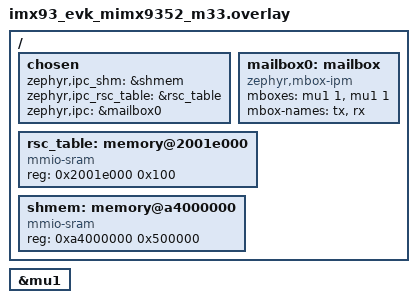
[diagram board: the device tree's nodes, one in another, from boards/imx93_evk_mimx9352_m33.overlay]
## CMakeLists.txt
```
cmake_minimum_required(VERSION 3.28.0)
# Copyright (c) 2020 STMicroelectronics
#
# SPDX-License-Identifier: Apache-2.0
#

find_package(Zephyr REQUIRED HINTS $ENV{ZEPHYR_BASE})

project(openamp_rsc_table_remote)

target_include_directories(app PRIVATE ${LIBMETAL_INCLUDE_DIR} ${OPENAMP_INCLUDE_DIR} ${PLATFORM_DIR})

target_sources(app PRIVATE src/main_remote.c)
```

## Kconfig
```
# Private config options for openamp sample app

# Copyright (c) 2020 STMicroelectronics
# SPDX-License-Identifier: Apache-2.0

# Workaround for not being able to have commas in macro arguments
DT_CHOSEN_Z_IPC := zephyr,ipc

config OPENAMP_IPC_DEV_NAME
	string
	default "$(dt_chosen_label,$(DT_CHOSEN_Z_IPC))"
	help
	  This option specifies the device name for the IPC device to be used

config OPENAMP_IPC_NOTIFY_CHAN
	int "Mailbox channel to use to notify the host"
	default 0

source "Kconfig.zephyr"
```

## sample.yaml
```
sample:
  description: This app provides an example of how to integrate OpenAMP
    with Zephyr including a resource table.
  name: OpenAMP with resource table example integration
tests:
  sample.ipc.openamp_rs_table:
    build_only: true
    platform_allow:
      - stm32mp157c_dk2
      - imx8mp_evk/mimx8ml8/adsp
    integration_platforms:
      - stm32mp157c_dk2
      - imx8mp_evk/mimx8ml8/adsp
    tags:
      - ipm
      - openamp
```

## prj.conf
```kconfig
CONFIG_KERNEL_BIN_NAME="zephyr_openamp_rsc_table"
CONFIG_PRINTK=n
CONFIG_IPM=y
CONFIG_MAIN_STACK_SIZE=1024
CONFIG_HEAP_MEM_POOL_SIZE=1024
CONFIG_OPENAMP=y
CONFIG_OPENAMP_RSC_TABLE_NUM_RPMSG_BUFF=8
CONFIG_OPENAMP_RSC_TABLE=y
CONFIG_OPENAMP_MASTER=n

CONFIG_SHELL=y
CONFIG_SHELL_BACKEND_RPMSG=y
```

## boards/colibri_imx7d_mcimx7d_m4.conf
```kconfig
CONFIG_IPM_IMX_MAX_DATA_SIZE_4=y
CONFIG_OPENAMP_WITH_DCACHE=y
CONFIG_OPENAMP_RSC_TABLE_NUM_RPMSG_BUFF=32

CONFIG_BUILD_OUTPUT_BIN=n
```

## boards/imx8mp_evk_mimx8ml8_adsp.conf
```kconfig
CONFIG_LOG_PRINTK=n
CONFIG_IPM_IMX_MAX_DATA_SIZE_16=n
CONFIG_IPM_IMX_MAX_DATA_SIZE_4=y
CONFIG_OPENAMP_WITH_DCACHE=y
CONFIG_IPM_IMX_FW_READY_REPLY=y
```

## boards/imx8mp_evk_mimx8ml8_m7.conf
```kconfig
CONFIG_LOG_PRINTK=n
CONFIG_IPM_IMX_MAX_DATA_SIZE_16=n
CONFIG_IPM_IMX_MAX_DATA_SIZE_4=y
CONFIG_OPENAMP_WITH_DCACHE=y
CONFIG_LOG=y
CONFIG_LOG_BACKEND_UART=y
CONFIG_LOG_DEFAULT_LEVEL=0
CONFIG_LOG_MODE_MINIMAL=y
CONFIG_OPENAMP_RSC_TABLE_IPM_RX_ID=1
CONFIG_OPENAMP_RSC_TABLE_IPM_TX_ID=0
```

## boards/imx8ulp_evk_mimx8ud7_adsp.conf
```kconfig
CONFIG_LOG_PRINTK=n
CONFIG_OPENAMP_WITH_DCACHE=y

CONFIG_MBOX=y
CONFIG_MBOX_INIT_PRIORITY=3

#vendor-specific resource table
CONFIG_OPENAMP_VENDOR_RSC_TABLE=y
CONFIG_OPENAMP_VENDOR_RSC_TABLE_FILE="nxp_resource_table.c"

#address translation support
CONFIG_OPENAMP_VENDOR_ADDR_TRANSLATION=y
CONFIG_OPENAMP_VENDOR_ADDR_TRANSLATION_FILE="nxp_addr_translation.h"
```

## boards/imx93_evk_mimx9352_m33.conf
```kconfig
CONFIG_CLOCK_CONTROL=y
CONFIG_CONSOLE=y
CONFIG_UART_CONSOLE=y
CONFIG_LOG=y
CONFIG_LOG_MODE_MINIMAL=y
CONFIG_MBOX_INIT_PRIORITY=0
CONFIG_OPENAMP_COPY_RSC_TABLE=y
```

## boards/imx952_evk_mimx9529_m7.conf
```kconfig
CONFIG_LOG=y
CONFIG_SHELL_BACKEND_RPMSG=n
CONFIG_PRINTK=y
CONFIG_OPENAMP_WITH_DCACHE=y
CONFIG_IPM_MBOX=y
CONFIG_MBOX_NXP_IMX_MU=y
CONFIG_LOG_MODE_MINIMAL=y
CONFIG_LOG_DEFAULT_LEVEL=3
CONFIG_OPENAMP_COPY_RSC_TABLE=y
```

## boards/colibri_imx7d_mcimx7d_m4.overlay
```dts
/*
 * Copyright (c) 2024 MAKEEN Energy A/S
 *
 * SPDX-License-Identifier: Apache-2.0
 */

/* Follow the board's documentation to modify the Linux DT accordingly */

/ {
	chosen {
		/* Use OCRAM 128kB because TCM 32kB is too small for the sample */
		zephyr,flash = &ocram_code;
		zephyr,ipc_shm = &ddr_shm;
		zephyr,ipc = &mub;
		zephyr,romstart = &ocram_s_code;
	};

	ddr_shm: memory1@90000000 {
		compatible = "mmio-sram";
		/* use DDR_SYS area as mmio, 0x90000000 0x10000 */
		reg = <0x90000000 0x10000>;
		status = "okay";
	};
};

&mub {
	status = "okay";
};
```

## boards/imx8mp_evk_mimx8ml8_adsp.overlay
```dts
/*
 * Copyright (c) 2023 NXP
 *
 * SPDX-License-Identifier: Apache-2.0
 */

/ {
	chosen {
		/*
		 * shared memory reserved for the inter-processor communication
		 */
		zephyr,ipc_shm = &dspsram3;
		zephyr,ipc = &mailbox0;
	};

	dspsram3: memory@942f0000 {
		compatible = "mmio-sram";
		reg = <0x942f0000 0x110000>;
	};
};

&mailbox0 {
	status = "okay";
};
```

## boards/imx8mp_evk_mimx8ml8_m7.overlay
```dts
/*
 * Copyright 2024 NXP
 *
 * SPDX-License-Identifier: Apache-2.0
 */

/ {
	chosen {
		/*
		 * shared memory reserved for the inter-processor communication
		 */
		zephyr,ipc_shm = &shram;
		zephyr,ipc = &mailbox0;
	};

	shram: memory@55000000 {
		compatible = "mmio-sram";
		reg = <0x55000000 0x500000>;
	};
};

&mailbox0 {
	status = "okay";
};
```

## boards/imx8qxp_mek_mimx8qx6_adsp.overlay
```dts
/*
 * Copyright 2024 NXP
 *
 * SPDX-License-Identifier: Apache-2.0
 */

/ {
	chosen {
		/*
		 * shared memory reserved for the inter-processor communication
		 */
		zephyr,ipc_shm = &dspsram3;
		zephyr,ipc = &mailbox0;
	};

	dspsram3: memory@942f0000 {
		compatible = "mmio-sram";
		reg = <0x942f0000 0x110000>;
	};
};

&mailbox0 {
	status = "okay";
};
```

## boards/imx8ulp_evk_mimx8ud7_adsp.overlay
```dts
/*
 * Copyright 2025 NXP
 *
 * SPDX-License-Identifier: Apache-2.0
 */

/ {
	chosen {
		/*
		 * shared memory reserved for the inter-processor communication
		 */
		zephyr,ipc_shm = &dspsram3;
		zephyr,ipc = &mailbox0;
	};

	mailbox0: mailbox {
		compatible = "zephyr,mbox-ipm";
		mboxes = <&mu3 0>, <&mu3 0>;
		mbox-names = "tx", "rx";
		status = "okay";
	};

	dspsram3: memory@1bef0000 {
		reg = <0x1bef0000 0x110000>;
	};
};

&mu3 {
	status = "okay";
};
```

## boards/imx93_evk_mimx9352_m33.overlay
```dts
/*
 * Copyright 2025 NXP
 *
 * SPDX-License-Identifier: Apache-2.0
 */

/ {
	chosen {
		/*
		 * shared memory reserved for the inter-processor communication
		 */
		zephyr,ipc_shm = &shmem;
		zephyr,ipc_rsc_table = &rsc_table;
		zephyr,ipc = &mailbox0;
	};

	mailbox0: mailbox {
		compatible = "zephyr,mbox-ipm";
		mboxes = <&mu1 1>, <&mu1 1>;
		mbox-names = "tx", "rx";
	};

	rsc_table: memory@2001e000 {
		compatible = "mmio-sram";
		reg = <0x2001e000 0x100>;
	};

	shmem: memory@a4000000 {
		compatible = "mmio-sram";
		reg = <0xa4000000 0x500000>;
	};
};

&mu1 {
	status = "okay";
};
```

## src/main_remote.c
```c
/*
 * Copyright (c) 2020, STMICROELECTRONICS
 *
 * SPDX-License-Identifier: Apache-2.0
 */

#include <zephyr/kernel.h>
#include <zephyr/device.h>
#include <string.h>
#include <stdio.h>
#include <stdlib.h>

#include <zephyr/drivers/ipm.h>

#include <openamp/open_amp.h>
#include <metal/sys.h>
#include <metal/io.h>
#include <resource_table.h>
#include <addr_translation.h>

#ifdef CONFIG_SHELL_BACKEND_RPMSG
#include <zephyr/shell/shell_rpmsg.h>
#endif

#include <zephyr/logging/log.h>
LOG_MODULE_REGISTER(openamp_rsc_table);

#define SHM_DEVICE_NAME	"shm"

/*
 * Lifecycle messages the Linux remoteproc driver exchanges over the mailbox,
 * from its own omap_remoteproc.h. Anything below the first of them is a vring
 * index rather than a command.
 */
#define RP_MBOX_SHUTDOWN     0xFFFFFF14U
#define RP_MBOX_SHUTDOWN_ACK 0xFFFFFF15U

#if !DT_HAS_CHOSEN(zephyr_ipc_shm)
#error "Sample requires definition of shared memory for rpmsg"
#endif

#if CONFIG_IPM_MAX_DATA_SIZE > 0

#define	IPM_SEND(dev, w, id, d, s) ipm_send(dev, w, id, d, s)
#else
#define IPM_SEND(dev, w, id, d, s) ipm_send(dev, w, id, NULL, 0)
#endif

/* Constants derived from device tree */
#define SHM_NODE		DT_CHOSEN(zephyr_ipc_shm)
#define SHM_START_ADDR	DT_REG_ADDR(SHM_NODE)
#define SHM_SIZE		DT_REG_SIZE(SHM_NODE)

#define APP_TASK_STACK_SIZE (1024)

/* Add 1024 extra bytes for the TTY task stack for the "tx_buff" buffer. */
#define APP_TTY_TASK_STACK_SIZE (1536)

K_THREAD_STACK_DEFINE(thread_mng_stack, APP_TASK_STACK_SIZE);
K_THREAD_STACK_DEFINE(thread_rp__client_stack, APP_TASK_STACK_SIZE);
K_THREAD_STACK_DEFINE(thread_tty_stack, APP_TTY_TASK_STACK_SIZE);

static struct k_thread thread_mng_data;
static struct k_thread thread_rp__client_data;
static struct k_thread thread_tty_data;

static const struct device *const ipm_handle =
	DEVICE_DT_GET(DT_CHOSEN(zephyr_ipc));

static metal_phys_addr_t shm_physmap = SHM_START_ADDR;
static metal_phys_addr_t rsc_tab_physmap;

static struct metal_io_region shm_io_data; /* shared memory */
static struct metal_io_region rsc_io_data; /* rsc_table memory */

struct rpmsg_rcv_msg {
	void *data;
	size_t len;
};

static struct metal_io_region *shm_io = &shm_io_data;

static struct metal_io_region *rsc_io = &rsc_io_data;
static struct rpmsg_virtio_device rvdev;

static void *rsc_table;
static struct rpmsg_device *rpdev;

static char rx_sc_msg[20];  /* should receive "Hello world!" */
static struct rpmsg_endpoint sc_ept;
static struct rpmsg_rcv_msg sc_msg = {.data = rx_sc_msg};

static struct rpmsg_endpoint tty_ept;
static struct rpmsg_rcv_msg tty_msg;

static K_SEM_DEFINE(data_sem, 0, 1);
static K_SEM_DEFINE(data_sc_sem, 0, 1);
static K_SEM_DEFINE(data_tty_sem, 0, 1);

/*
 * Answers the shutdown request of the host and parks the core where the host
 * expects to find it.
 *
 * Having asked, the host waits for the acknowledgment and then gives the
 * core two milliseconds to reach WFI before it gives up and reports the stop
 * as timed out. There is nothing left to return to, so park here rather than
 * unwind through a mailbox interrupt the host is about to halt anyway.
 */
static void platform_shutdown(void)
{
	uint32_t ack = RP_MBOX_SHUTDOWN_ACK;

	/*
	 * A full mailbox is the one way this can fail, and dropping the
	 * acknowledgment costs the host a five second wait and leaves it
	 * unable to load anything else, so give the mailbox room to drain.
	 */
	for (int i = 0; i < 100; i++) {
		if (IPM_SEND(ipm_handle, 0, ack, &ack, sizeof(ack)) == 0) {
			break;
		}

		k_busy_wait(100);
	}

	/*
	 * Nothing is left to return to, so park the core here rather than
	 * unwind through a mailbox interrupt the host is about to halt
	 * anyway. k_cpu_idle() is what puts the core in the state the host
	 * looks for before halting it.
	 */
	for (;;) {
		k_cpu_idle();
	}
}

static void platform_ipm_callback(const struct device *dev, void *context,
				  uint32_t id, volatile void *data)
{
	/*
	 * The message itself arrives as the payload; id carries the mailbox
	 * channel it came in on.
	 */
	uint32_t msg = (data != NULL) ? *(volatile uint32_t *)data : 0;

	LOG_DBG("%s: msg 0x%08x received from mb %d", __func__, msg, id);

	if (msg == RP_MBOX_SHUTDOWN) {
		platform_shutdown();
	}

	k_sem_give(&data_sem);
}

static int rpmsg_recv_cs_callback(struct rpmsg_endpoint *ept, void *data,
				  size_t len, uint32_t src, void *priv)
{
	memcpy(sc_msg.data, data, len);
	sc_msg.len = len;
	k_sem_give(&data_sc_sem);

	return RPMSG_SUCCESS;
}

static int rpmsg_recv_tty_callback(struct rpmsg_endpoint *ept, void *data,
				   size_t len, uint32_t src, void *priv)
{
	struct rpmsg_rcv_msg *msg = priv;

	rpmsg_hold_rx_buffer(ept, data);
	msg->data = data;
	msg->len = len;
	k_sem_give(&data_tty_sem);

	return RPMSG_SUCCESS;
}

static void receive_message(unsigned char **msg, unsigned int *len)
{
	int status = k_sem_take(&data_sem, K_FOREVER);

	if (status == 0) {
		rproc_virtio_notified(rvdev.vdev, VRING1_ID);
	}
}

static void new_service_cb(struct rpmsg_device *rdev, const char *name,
			   uint32_t src)
{
	LOG_ERR("%s: unexpected ns service receive for name %s",
		__func__, name);
}

int mailbox_notify(void *priv, uint32_t id)
{
	ARG_UNUSED(priv);

	LOG_DBG("%s: msg received", __func__);
	IPM_SEND(ipm_handle, 0, id, &id, 4);

	return 0;
}

int platform_init(void)
{
	int rsc_size;
	struct metal_init_params metal_params = METAL_INIT_DEFAULTS;
	int status;

	status = metal_init(&metal_params);
	if (status) {
		LOG_ERR("metal_init: failed: %d", status);
		return -1;
	}

	/* declare shared memory region */
	metal_io_init(shm_io, (void *)SHM_START_ADDR, &shm_physmap,
		      SHM_SIZE, -1, 0, addr_translation_get_ops(shm_physmap));

	/* declare resource table region */
	rsc_table_get(&rsc_table, &rsc_size);
	rsc_tab_physmap = (uintptr_t)rsc_table;

	metal_io_init(rsc_io, rsc_table,
		      &rsc_tab_physmap, rsc_size, -1, 0, NULL);

	/* setup IPM */
	if (!device_is_ready(ipm_handle)) {
		LOG_ERR("IPM device is not ready");
		return -1;
	}

	ipm_register_callback(ipm_handle, platform_ipm_callback, NULL);

	status = ipm_set_enabled(ipm_handle, 1);
	if (status) {
		LOG_ERR("ipm_set_enabled failed");
		return -1;
	}

	return 0;
}

static void cleanup_system(void)
{
	ipm_set_enabled(ipm_handle, 0);
	rpmsg_deinit_vdev(&rvdev);
	metal_finish();
}

struct  rpmsg_device *
platform_create_rpmsg_vdev(unsigned int vdev_index,
			   unsigned int role,
			   void (*rst_cb)(struct virtio_device *vdev),
			   rpmsg_ns_bind_cb ns_cb)
{
	struct fw_rsc_vdev_vring *vring_rsc;
	struct virtio_device *vdev;
	int ret;

	vdev = rproc_virtio_create_vdev(VIRTIO_DEV_DEVICE, VDEV_ID,
					rsc_table_to_vdev(rsc_table),
					rsc_io, NULL, mailbox_notify, NULL);

	if (!vdev) {
		LOG_ERR("failed to create vdev");
		return NULL;
	}

	/* wait master rpmsg init completion */
	rproc_virtio_wait_remote_ready(vdev);

	vring_rsc = rsc_table_get_vring0(rsc_table);
	ret = rproc_virtio_init_vring(vdev, 0, vring_rsc->notifyid,
				      (void *)vring_rsc->da, rsc_io,
				      vring_rsc->num, vring_rsc->align);
	if (ret) {
		LOG_ERR("failed to init vring 0");
		goto failed;
	}

	vring_rsc = rsc_table_get_vring1(rsc_table);
	ret = rproc_virtio_init_vring(vdev, 1, vring_rsc->notifyid,
				      (void *)vring_rsc->da, rsc_io,
				      vring_rsc->num, vring_rsc->align);
	if (ret) {
		LOG_ERR("failed to init vring 1");
		goto failed;
	}

	ret = rpmsg_init_vdev(&rvdev, vdev, ns_cb, shm_io, NULL);
	if (ret) {
		LOG_ERR("failed rpmsg_init_vdev");
		goto failed;
	}

	return rpmsg_virtio_get_rpmsg_device(&rvdev);

failed:
	rproc_virtio_remove_vdev(vdev);

	return NULL;
}

void app_rpmsg_client_sample(void *arg1, void *arg2, void *arg3)
{
	ARG_UNUSED(arg1);
	ARG_UNUSED(arg2);
	ARG_UNUSED(arg3);

	unsigned int msg_cnt = 0;
	int ret = 0;

	k_sem_take(&data_sc_sem,  K_FOREVER);

	LOG_INF("OpenAMP[remote] Linux sample client responder started");

	ret = rpmsg_create_ept(&sc_ept, rpdev, "rpmsg-client-sample",
			       RPMSG_ADDR_ANY, RPMSG_ADDR_ANY,
			       rpmsg_recv_cs_callback, NULL);
	if (ret) {
		LOG_ERR("[Linux sample client] Could not create endpoint: %d", ret);
		goto task_end;
	}

	while (msg_cnt < 100) {
		k_sem_take(&data_sc_sem,  K_FOREVER);
		msg_cnt++;
		LOG_INF("[Linux sample client] incoming msg %d: %.*s", msg_cnt, sc_msg.len,
			(char *)sc_msg.data);
		rpmsg_send(&sc_ept, sc_msg.data, sc_msg.len);
	}
	rpmsg_destroy_ept(&sc_ept);

task_end:
	LOG_INF("OpenAMP Linux sample client responder ended");
}

void app_rpmsg_tty(void *arg1, void *arg2, void *arg3)
{
	ARG_UNUSED(arg1);
	ARG_UNUSED(arg2);
	ARG_UNUSED(arg3);

	unsigned char tx_buff[512];
	int ret = 0;

	k_sem_take(&data_tty_sem,  K_FOREVER);

	LOG_INF("OpenAMP[remote] Linux TTY responder started");

	tty_ept.priv = &tty_msg;
	ret = rpmsg_create_ept(&tty_ept, rpdev, "rpmsg-tty",
			       RPMSG_ADDR_ANY, RPMSG_ADDR_ANY,
			       rpmsg_recv_tty_callback, NULL);
	if (ret) {
		LOG_ERR("[Linux TTY] Could not create endpoint: %d", ret);
		goto task_end;
	}

	while (tty_ept.addr !=  RPMSG_ADDR_ANY) {
		k_sem_take(&data_tty_sem,  K_FOREVER);
		if (tty_msg.len) {
			LOG_INF("[Linux TTY] incoming msg: %.*s",
				(int)tty_msg.len, (char *)tty_msg.data);
			snprintf(tx_buff, 13, "TTY 0x%04x: ", tty_ept.addr);
			memcpy(&tx_buff[12], tty_msg.data, tty_msg.len);
			rpmsg_send(&tty_ept, tx_buff, tty_msg.len + 12);
			rpmsg_release_rx_buffer(&tty_ept, tty_msg.data);
		}
		tty_msg.len = 0;
		tty_msg.data = NULL;
	}
	rpmsg_destroy_ept(&tty_ept);

task_end:
	LOG_INF("OpenAMP Linux TTY responder ended");
}

void rpmsg_mng_task(void *arg1, void *arg2, void *arg3)
{
	ARG_UNUSED(arg1);
	ARG_UNUSED(arg2);
	ARG_UNUSED(arg3);

	unsigned char *msg;
	unsigned int len;
	int ret = 0;

	LOG_INF("OpenAMP[remote] Linux responder demo started");

	/* Initialize platform */
	ret = platform_init();
	if (ret) {
		LOG_ERR("Failed to initialize platform");
		ret = -1;
		goto task_end;
	}

	rpdev = platform_create_rpmsg_vdev(0, VIRTIO_DEV_DEVICE, NULL,
					   new_service_cb);
	if (!rpdev) {
		LOG_ERR("Failed to create rpmsg virtio device");
		ret = -1;
		goto task_end;
	}

#ifdef CONFIG_SHELL_BACKEND_RPMSG
	(void)shell_backend_rpmsg_init_transport(rpdev);
#endif

	/* start the rpmsg clients */
	k_sem_give(&data_sc_sem);
	k_sem_give(&data_tty_sem);

	while (1) {
		receive_message(&msg, &len);
	}

task_end:
	cleanup_system();

	LOG_INF("OpenAMP demo ended");
}

int main(void)
{
	LOG_INF("Starting application threads!");
	k_thread_create(&thread_mng_data, thread_mng_stack, APP_TASK_STACK_SIZE,
			rpmsg_mng_task,
			NULL, NULL, NULL, K_PRIO_COOP(8), 0, K_NO_WAIT);
	k_thread_create(&thread_rp__client_data, thread_rp__client_stack, APP_TASK_STACK_SIZE,
			app_rpmsg_client_sample,
			NULL, NULL, NULL, K_PRIO_COOP(7), 0, K_NO_WAIT);
	k_thread_create(&thread_tty_data, thread_tty_stack, APP_TTY_TASK_STACK_SIZE,
			app_rpmsg_tty,
			NULL, NULL, NULL, K_PRIO_COOP(7), 0, K_NO_WAIT);
	return 0;
}
```
